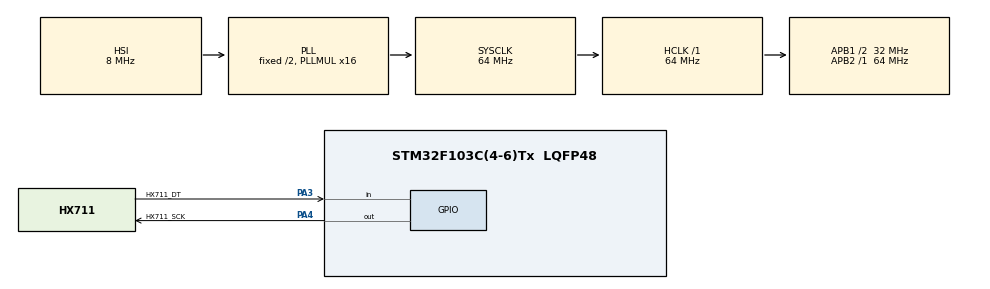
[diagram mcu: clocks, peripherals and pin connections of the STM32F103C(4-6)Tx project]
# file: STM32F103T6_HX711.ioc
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Mcu.Family=STM32F1
Mcu.Name=STM32F103C(4-6)Tx
Mcu.Package=LQFP48
NVIC.PriorityGroup=NVIC_PRIORITYGROUP_4
PA3.GPIO_Label=HX711_DT
PA3.Signal=GPIO_Input
PA4.GPIO_Label=HX711_SCK
PA4.Signal=GPIO_Output
ProjectManager.HeapSize=0x200
ProjectManager.StackSize=0x400
ProjectManager.TargetToolchain=STM32CubeIDE
RCC.AHBFreq_Value=64000000
RCC.APB1CLKDivider=RCC_HCLK_DIV2
RCC.APB1Freq_Value=32000000
RCC.APB1TimFreq_Value=64000000
RCC.APB2Freq_Value=64000000
RCC.APB2TimFreq_Value=64000000
RCC.HCLKFreq_Value=64000000
RCC.PLLMUL=RCC_PLL_MUL16
RCC.SYSCLKFreq_VALUE=64000000
RCC.SYSCLKSource=RCC_SYSCLKSOURCE_PLLCLK
RCC.USBFreq_Value=64000000
board=custom

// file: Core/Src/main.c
/* USER CODE BEGIN Header */
/**
  ******************************************************************************
  * @file           : main.c
  * @brief          : Main program body
  ******************************************************************************
  * @attention
  *
  * Copyright (c) 2023 STMicroelectronics.
  * All rights reserved.
  *
  * This software is licensed under terms that can be found in the LICENSE file
  * in the root directory of this software component.
  * If no LICENSE file comes with this software, it is provided AS-IS.
  *
  ******************************************************************************
  */
/* USER CODE END Header */
#include "main.h"

/* USER CODE BEGIN Includes */
#include "hx711.h"
/* USER CODE END Includes */

/* USER CODE BEGIN PV */
int32_t weight;
int32_t myWeight;
/* USER CODE END PV */

void SystemClock_Config(void);
static void MX_GPIO_Init(void);

int main(void)
{

  /* MCU Configuration--------------------------------------------------------*/

  /* Reset of all peripherals, Initializes the Flash interface and the Systick. */
  HAL_Init();

  /* Configure the system clock */
  SystemClock_Config();

  /* Initialize all configured peripherals */
  MX_GPIO_Init();
  /* USER CODE BEGIN 2 */
  hx711_init(HX711_DT_GPIO_Port, HX711_DT_Pin, HX711_SCK_GPIO_Port, HX711_SCK_Pin);
  HAL_Delay(100);
  hx711_turnOn();
  hx711_tara(5);
  weight = 0;
  /* USER CODE END 2 */

  /* Infinite loop */
  /* USER CODE BEGIN WHILE */
  while (1)
  {
	  weight = hx711_getWeight();
	  myWeight = weight / 1000;
	  HAL_Delay(200);
    /* USER CODE END WHILE */

  }
}

void SystemClock_Config(void)
{
  RCC_OscInitTypeDef RCC_OscInitStruct = {0};
  RCC_ClkInitTypeDef RCC_ClkInitStruct = {0};

  /** Initializes the RCC Oscillators according to the specified parameters
  * in the RCC_OscInitTypeDef structure.
  */
  RCC_OscInitStruct.OscillatorType = RCC_OSCILLATORTYPE_HSI;
  RCC_OscInitStruct.HSIState = RCC_HSI_ON;
  RCC_OscInitStruct.HSICalibrationValue = RCC_HSICALIBRATION_DEFAULT;
  RCC_OscInitStruct.PLL.PLLState = RCC_PLL_ON;
  RCC_OscInitStruct.PLL.PLLSource = RCC_PLLSOURCE_HSI_DIV2;
  RCC_OscInitStruct.PLL.PLLMUL = RCC_PLL_MUL16;
  if (HAL_RCC_OscConfig(&RCC_OscInitStruct) != HAL_OK)
  {
    Error_Handler();
  }

  /** Initializes the CPU, AHB and APB buses clocks
  */
  RCC_ClkInitStruct.ClockType = RCC_CLOCKTYPE_HCLK|RCC_CLOCKTYPE_SYSCLK
                              |RCC_CLOCKTYPE_PCLK1|RCC_CLOCKTYPE_PCLK2;
  RCC_ClkInitStruct.SYSCLKSource = RCC_SYSCLKSOURCE_PLLCLK;
  RCC_ClkInitStruct.AHBCLKDivider = RCC_SYSCLK_DIV1;
  RCC_ClkInitStruct.APB1CLKDivider = RCC_HCLK_DIV2;
  RCC_ClkInitStruct.APB2CLKDivider = RCC_HCLK_DIV1;

  if (HAL_RCC_ClockConfig(&RCC_ClkInitStruct, FLASH_LATENCY_2) != HAL_OK)
  {
    Error_Handler();
  }
}

static void MX_GPIO_Init(void)
{
  GPIO_InitTypeDef GPIO_InitStruct = {0};

  /* GPIO Ports Clock Enable */
  __HAL_RCC_GPIOA_CLK_ENABLE();

  /*Configure GPIO pin Output Level */
  HAL_GPIO_WritePin(HX711_SCK_GPIO_Port, HX711_SCK_Pin, GPIO_PIN_RESET);

  /*Configure GPIO pin : HX711_DT_Pin */
  GPIO_InitStruct.Pin = HX711_DT_Pin;
  GPIO_InitStruct.Mode = GPIO_MODE_INPUT;
  GPIO_InitStruct.Pull = GPIO_NOPULL;
  HAL_GPIO_Init(HX711_DT_GPIO_Port, &GPIO_InitStruct);

  /*Configure GPIO pin : HX711_SCK_Pin */
  GPIO_InitStruct.Pin = HX711_SCK_Pin;
  GPIO_InitStruct.Mode = GPIO_MODE_OUTPUT_PP;
  GPIO_InitStruct.Pull = GPIO_NOPULL;
  GPIO_InitStruct.Speed = GPIO_SPEED_FREQ_LOW;
  HAL_GPIO_Init(HX711_SCK_GPIO_Port, &GPIO_InitStruct);

}

void Error_Handler(void)
{
  __disable_irq();
  while (1)
  {
  }
}
